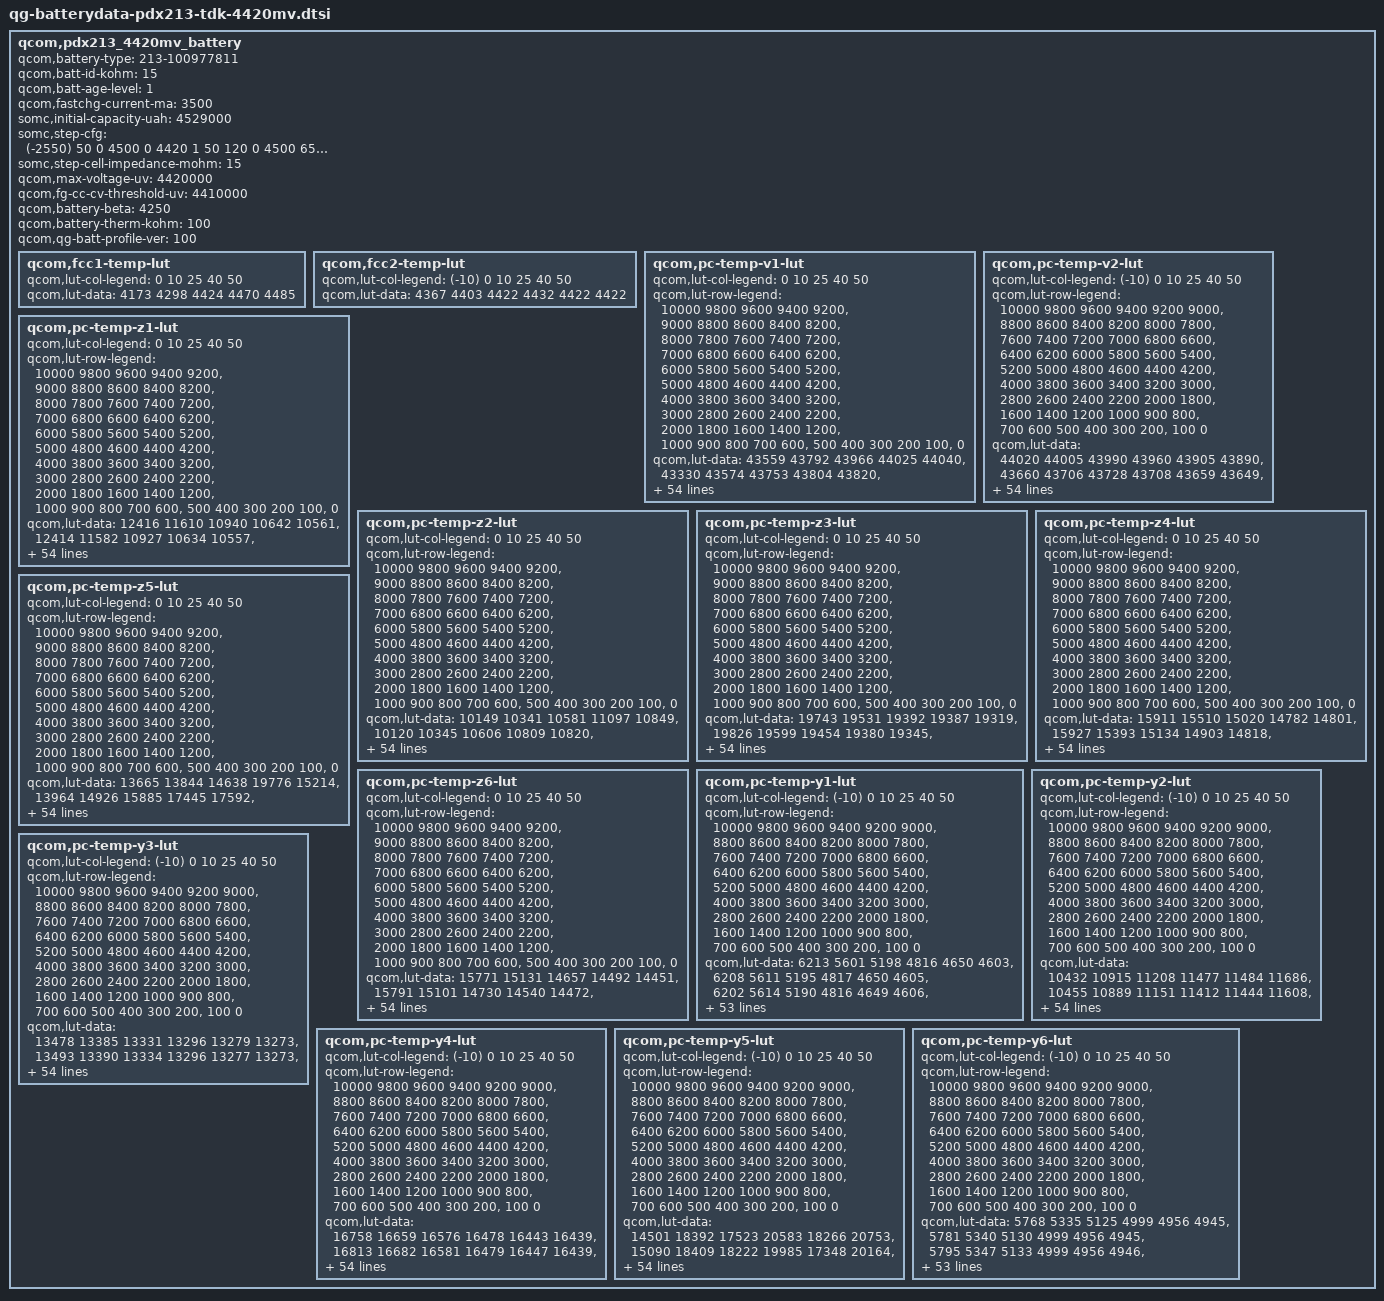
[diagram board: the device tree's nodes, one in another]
qcom,pdx213_4420mv_battery {
	/* Added or Modified by SOMC */
	qcom,battery-type = "213-100977811";
	qcom,batt-id-kohm = <15>;
	qcom,batt-age-level = <1>;
	qcom,fastchg-current-ma = <3500>;
	somc,initial-capacity-uah = <4529000>;
	somc,step-cfg = <
		(-2550) 50    0 4500    0 4420 1
		   50  120    0 4500  650 4420 2
		  120  150    0 4100 2150 4420 3
		  120  150 4100 4200 1750 4420 3
		  120  150 4200 4300 1300 4420 3
		  120  150 4300 4500  850 4420 3
		  150  200    0 4100 2400 4420 3
		  150  200 4100 4200 1950 4420 3
		  150  200 4200 4300 1750 4420 3
		  150  200 4300 4500 1300 4420 3
		  200  450    0 4200 4150 4420 3
		  200  450 4200 4250 3050 4420 3
		  200  450 4250 4350 1950 4420 3
		  200  450 4350 4500 1300 4420 3
		  450  550    0 4500 1300 4200 4
		  550 2550    0 4500    0 4200 5
	>;
	somc,step-cell-impedance-mohm = <15>;

	/* Prepared by Qualcomm */
    /* 4764138_SoMC_Licht_4375mAh_averaged_MasterSlave_Sept10th2020 */
    qcom,max-voltage-uv = <4420000>;
    qcom,fg-cc-cv-threshold-uv = <4410000>;
    /* qcom,fastchg-current-ma = <1500>; */
    /* qcom,batt-id-kohm = <0>; */
    qcom,battery-beta = <4250>;
    qcom,battery-therm-kohm = <100>;
    /* qcom,battery-type = "4764138_SoMC_Licht_4375mAh_averaged_MasterSlave_Sept10th2020"; */
    qcom,qg-batt-profile-ver = <100>;

	qcom,fcc1-temp-lut {
		qcom,lut-col-legend = <0 10 25 40 50>;
		qcom,lut-data = <4173 4298 4424 4470 4485>;
	};

	qcom,fcc2-temp-lut {
		qcom,lut-col-legend = <(-10) 0 10 25 40 50>;
		qcom,lut-data = <4367 4403 4422 4432 4422 4422>;
	};

	qcom,pc-temp-v1-lut {
		qcom,lut-col-legend = <0 10 25 40 50>;
		qcom,lut-row-legend = <10000 9800 9600 9400 9200>,
			<9000 8800 8600 8400 8200>,
			<8000 7800 7600 7400 7200>,
			<7000 6800 6600 6400 6200>,
			<6000 5800 5600 5400 5200>,
			<5000 4800 4600 4400 4200>,
			<4000 3800 3600 3400 3200>,
			<3000 2800 2600 2400 2200>,
			<2000 1800 1600 1400 1200>,
			<1000 900 800 700 600>,
			<500 400 300 200 100>,
			<0>;
		qcom,lut-data = <43559 43792 43966 44025 44040>,
			<43330 43574 43753 43804 43820>,
			<43101 43351 43542 43593 43612>,
			<42873 43123 43326 43385 43401>,
			<42643 42892 43099 43166 43183>,
			<42414 42658 42864 42935 42959>,
			<42188 42423 42628 42702 42729>,
			<41965 42190 42389 42465 42494>,
			<41747 41961 42151 42228 42256>,
			<41535 41736 41915 41992 42021>,
			<41326 41516 41683 41758 41790>,
			<41126 41300 41457 41529 41562>,
			<40936 41092 41237 41306 41337>,
			<40750 40896 41025 41090 41116>,
			<40556 40705 40818 40877 40903>,
			<40357 40515 40618 40671 40697>,
			<40179 40325 40427 40475 40499>,
			<40033 40148 40245 40290 40309>,
			<39898 39996 40072 40112 40127>,
			<39753 39848 39919 39948 39958>,
			<39599 39670 39760 39790 39799>,
			<39436 39454 39534 39599 39616>,
			<39252 39244 39235 39343 39374>,
			<39053 39042 39022 39110 39141>,
			<38889 38859 38906 38955 38974>,
			<38761 38747 38813 38831 38836>,
			<38659 38679 38716 38715 38715>,
			<38590 38617 38621 38609 38609>,
			<38539 38546 38532 38512 38512>,
			<38494 38475 38449 38422 38419>,
			<38449 38410 38375 38341 38334>,
			<38406 38349 38308 38268 38256>,
			<38365 38294 38250 38201 38185>,
			<38325 38245 38196 38140 38118>,
			<38287 38202 38151 38088 38060>,
			<38252 38162 38106 38039 38003>,
			<38218 38129 38062 37986 37937>,
			<38174 38092 38017 37931 37864>,
			<38104 38028 37957 37865 37785>,
			<38013 37930 37870 37780 37702>,
			<37907 37820 37766 37680 37610>,
			<37779 37700 37648 37564 37495>,
			<37633 37561 37511 37429 37359>,
			<37469 37392 37346 37271 37200>,
			<37320 37243 37191 37124 37059>,
			<37219 37140 37093 37028 36969>,
			<37184 37113 37066 37007 36945>,
			<37153 37088 37045 36990 36929>,
			<37123 37068 37030 36973 36916>,
			<37082 37034 37000 36940 36878>,
			<36941 36891 36830 36739 36650>,
			<36523 36471 36418 36323 36228>,
			<35956 35906 35858 35761 35666>,
			<35175 35125 35098 35001 34903>,
			<33824 33839 33933 33838 33735>,
			<30000 30000 30000 30000 30000>;
	};

	qcom,pc-temp-v2-lut {
		qcom,lut-col-legend = <(-10) 0 10 25 40 50>;
		qcom,lut-row-legend = <10000 9800 9600 9400 9200 9000>,
			<8800 8600 8400 8200 8000 7800>,
			<7600 7400 7200 7000 6800 6600>,
			<6400 6200 6000 5800 5600 5400>,
			<5200 5000 4800 4600 4400 4200>,
			<4000 3800 3600 3400 3200 3000>,
			<2800 2600 2400 2200 2000 1800>,
			<1600 1400 1200 1000 900 800>,
			<700 600 500 400 300 200>,
			<100 0>;
		qcom,lut-data = <44020 44005 43990 43960 43905 43890>,
			<43660 43706 43728 43708 43659 43649>,
			<43336 43426 43475 43462 43420 43414>,
			<43056 43166 43234 43226 43187 43184>,
			<42817 42926 43004 42998 42962 42960>,
			<42581 42689 42772 42769 42735 42734>,
			<42328 42447 42533 42533 42502 42501>,
			<42075 42205 42292 42295 42268 42266>,
			<41840 41969 42055 42060 42035 42033>,
			<41618 41735 41820 41825 41803 41801>,
			<41404 41505 41590 41594 41574 41573>,
			<41200 41274 41364 41367 41349 41351>,
			<40997 41049 41144 41145 41129 41132>,
			<40766 40855 40935 40931 40916 40920>,
			<40500 40686 40734 40723 40707 40711>,
			<40233 40494 40537 40522 40506 40511>,
			<39980 40233 40348 40324 40314 40318>,
			<39736 39954 40154 40136 40130 40133>,
			<39515 39722 39932 39965 39957 39959>,
			<39313 39518 39687 39806 39793 39795>,
			<39118 39322 39454 39616 39607 39609>,
			<38913 39126 39235 39360 39368 39374>,
			<38714 38942 39035 39109 39131 39140>,
			<38546 38776 38867 38921 38946 38955>,
			<38394 38625 38720 38762 38785 38794>,
			<38277 38485 38587 38627 38650 38658>,
			<38198 38352 38465 38512 38537 38547>,
			<38135 38230 38354 38410 38437 38447>,
			<38075 38122 38256 38314 38343 38352>,
			<38019 38024 38165 38225 38257 38262>,
			<37964 37954 38076 38143 38179 38181>,
			<37909 37906 37987 38068 38107 38108>,
			<37855 37868 37907 37998 38039 38037>,
			<37797 37831 37845 37937 37971 37971>,
			<37738 37799 37794 37880 37905 37906>,
			<37675 37762 37752 37817 37827 37821>,
			<37607 37725 37720 37748 37735 37704>,
			<37532 37680 37684 37675 37639 37586>,
			<37453 37607 37631 37597 37549 37493>,
			<37365 37501 37562 37515 37459 37406>,
			<37275 37389 37474 37423 37365 37312>,
			<37186 37272 37355 37321 37266 37213>,
			<37099 37139 37217 37198 37148 37094>,
			<37013 36986 37061 37055 37010 36956>,
			<36923 36851 36907 36922 36885 36834>,
			<36823 36756 36821 36877 36853 36803>,
			<36770 36718 36794 36859 36842 36789>,
			<36704 36680 36753 36839 36824 36774>,
			<36642 36634 36699 36811 36801 36754>,
			<36557 36550 36617 36737 36740 36678>,
			<36416 36350 36399 36492 36465 36369>,
			<36138 35911 35924 35986 35981 35881>,
			<35641 35201 35256 35335 35344 35238>,
			<34806 34127 34320 34441 34472 34354>,
			<33591 32536 32866 33159 33232 33107>,
			<31815 29576 29511 29554 29608 29574>;
	};

	qcom,pc-temp-z1-lut {
		qcom,lut-col-legend = <0 10 25 40 50>;
		qcom,lut-row-legend = <10000 9800 9600 9400 9200>,
			<9000 8800 8600 8400 8200>,
			<8000 7800 7600 7400 7200>,
			<7000 6800 6600 6400 6200>,
			<6000 5800 5600 5400 5200>,
			<5000 4800 4600 4400 4200>,
			<4000 3800 3600 3400 3200>,
			<3000 2800 2600 2400 2200>,
			<2000 1800 1600 1400 1200>,
			<1000 900 800 700 600>,
			<500 400 300 200 100>,
			<0>;
		qcom,lut-data = <12416 11610 10940 10642 10561>,
			<12414 11582 10927 10634 10557>,
			<12396 11564 10921 10629 10555>,
			<12377 11550 10914 10625 10553>,
			<12361 11539 10906 10623 10552>,
			<12345 11528 10898 10621 10551>,
			<12331 11518 10892 10619 10550>,
			<12309 11511 10887 10617 10549>,
			<12290 11504 10884 10615 10548>,
			<12274 11497 10881 10614 10547>,
			<12260 11495 10878 10613 10547>,
			<12258 11493 10877 10613 10546>,
			<12256 11492 10875 10612 10547>,
			<12252 11489 10875 10612 10549>,
			<12247 11485 10876 10612 10549>,
			<12241 11482 10878 10613 10549>,
			<12237 11477 10878 10613 10549>,
			<12241 11474 10878 10614 10550>,
			<12250 11481 10878 10615 10551>,
			<12254 11493 10880 10617 10553>,
			<12253 11498 10884 10618 10554>,
			<12253 11500 10887 10620 10556>,
			<12263 11503 10891 10623 10558>,
			<12285 11506 10895 10626 10561>,
			<12297 11510 10899 10629 10564>,
			<12298 11515 10904 10632 10566>,
			<12298 11523 10908 10635 10568>,
			<12298 11528 10913 10638 10570>,
			<12301 11528 10917 10640 10572>,
			<12303 11528 10921 10643 10574>,
			<12306 11529 10926 10646 10576>,
			<12308 11535 10929 10648 10577>,
			<12311 11543 10933 10650 10579>,
			<12322 11549 10937 10652 10580>,
			<12335 11555 10941 10655 10582>,
			<12343 11561 10946 10657 10584>,
			<12349 11566 10951 10660 10587>,
			<12356 11572 10957 10663 10589>,
			<12369 11580 10963 10666 10591>,
			<12386 11593 10968 10669 10593>,
			<12408 11605 10973 10672 10594>,
			<12440 11616 10980 10674 10596>,
			<12445 11623 10987 10676 10598>,
			<12418 11623 10991 10678 10599>,
			<12426 11629 10998 10681 10601>,
			<12433 11639 11003 10683 10601>,
			<12439 11638 11002 10683 10603>,
			<12412 11629 11003 10683 10602>,
			<12427 11644 11003 10684 10603>,
			<12438 11640 11007 10687 10606>,
			<12456 11660 11024 10692 10609>,
			<12461 11670 11034 10699 10615>,
			<12487 11703 11048 10710 10624>,
			<12542 11736 11075 10726 10637>,
			<12542 11736 11075 10726 10637>,
			<12542 11736 11075 10726 10637>;
	};

	qcom,pc-temp-z2-lut {
		qcom,lut-col-legend = <0 10 25 40 50>;
		qcom,lut-row-legend = <10000 9800 9600 9400 9200>,
			<9000 8800 8600 8400 8200>,
			<8000 7800 7600 7400 7200>,
			<7000 6800 6600 6400 6200>,
			<6000 5800 5600 5400 5200>,
			<5000 4800 4600 4400 4200>,
			<4000 3800 3600 3400 3200>,
			<3000 2800 2600 2400 2200>,
			<2000 1800 1600 1400 1200>,
			<1000 900 800 700 600>,
			<500 400 300 200 100>,
			<0>;
		qcom,lut-data = <10149 10341 10581 11097 10849>,
			<10120 10345 10606 10809 10820>,
			<10093 10331 10562 10811 10829>,
			<10074 10289 10516 10734 10851>,
			<10063 10247 10492 10708 10857>,
			<10056 10224 10476 10708 10832>,
			<10052 10207 10477 10711 10809>,
			<10049 10204 10495 10717 10813>,
			<10048 10228 10513 10725 10823>,
			<10053 10261 10522 10731 10815>,
			<10065 10279 10530 10735 10747>,
			<10077 10292 10539 10728 10701>,
			<10088 10306 10554 10660 10703>,
			<10098 10323 10568 10587 10708>,
			<10108 10340 10579 10585 10715>,
			<10117 10354 10588 10601 10738>,
			<10135 10366 10595 10619 10754>,
			<10216 10375 10600 10644 10761>,
			<10305 10382 10604 10666 10769>,
			<10307 10389 10607 10672 10779>,
			<10246 10404 10610 10673 10802>,
			<10207 10438 10620 10691 10839>,
			<10224 10459 10645 10757 10948>,
			<10255 10440 10656 10808 11036>,
			<10277 10408 10646 10852 11013>,
			<10290 10402 10636 10925 10949>,
			<10299 10413 10640 10921 10893>,
			<10301 10423 10653 10808 10805>,
			<10300 10424 10656 10722 10730>,
			<10300 10424 10614 10700 10698>,
			<10304 10425 10570 10686 10675>,
			<10311 10433 10571 10692 10673>,
			<10317 10444 10584 10733 10691>,
			<10325 10456 10605 10767 10716>,
			<10332 10471 10673 10787 10770>,
			<10338 10482 10735 10809 10850>,
			<10343 10490 10744 10847 10925>,
			<10349 10499 10741 10923 11001>,
			<10359 10516 10751 10981 11058>,
			<10369 10539 10786 11016 11121>,
			<10369 10548 10813 11043 11169>,
			<10359 10542 10810 11062 11138>,
			<10357 10538 10803 11076 11065>,
			<10371 10546 10819 11071 11084>,
			<10579 10632 10849 11038 11099>,
			<10417 10685 10887 10956 11090>,
			<10267 10712 10841 10972 11082>,
			<10197 10752 10813 10967 11050>,
			<10121 10982 10808 10952 11130>,
			<10003 11047 10811 11016 11246>,
			<10001 10950 11007 10886 10867>,
			<9865 10915 10960 10756 10729>,
			<9700 10814 10888 10674 10608>,
			<9584 10597 10811 10611 10570>,
			<9584 10597 10811 10611 10570>,
			<9584 10597 10811 10611 10570>;
	};

	qcom,pc-temp-z3-lut {
		qcom,lut-col-legend = <0 10 25 40 50>;
		qcom,lut-row-legend = <10000 9800 9600 9400 9200>,
			<9000 8800 8600 8400 8200>,
			<8000 7800 7600 7400 7200>,
			<7000 6800 6600 6400 6200>,
			<6000 5800 5600 5400 5200>,
			<5000 4800 4600 4400 4200>,
			<4000 3800 3600 3400 3200>,
			<3000 2800 2600 2400 2200>,
			<2000 1800 1600 1400 1200>,
			<1000 900 800 700 600>,
			<500 400 300 200 100>,
			<0>;
		qcom,lut-data = <19743 19531 19392 19387 19319>,
			<19826 19599 19454 19380 19345>,
			<19866 19631 19478 19401 19367>,
			<19879 19647 19487 19409 19382>,
			<19881 19655 19487 19410 19385>,
			<19881 19655 19487 19406 19377>,
			<19880 19652 19484 19402 19368>,
			<19876 19647 19473 19396 19366>,
			<19870 19631 19463 19389 19364>,
			<19859 19612 19458 19386 19361>,
			<19841 19603 19454 19383 19352>,
			<19825 19598 19448 19380 19346>,
			<19807 19592 19438 19368 19343>,
			<19793 19584 19432 19357 19342>,
			<19787 19577 19431 19356 19338>,
			<19784 19572 19430 19355 19332>,
			<19782 19570 19428 19354 19328>,
			<19779 19567 19425 19347 19327>,
			<19772 19564 19422 19341 19326>,
			<19769 19560 19419 19340 19325>,
			<19767 19563 19416 19340 19323>,
			<19768 19581 19421 19340 19322>,
			<19774 19593 19440 19345 19326>,
			<19781 19591 19448 19352 19332>,
			<19784 19585 19429 19361 19349>,
			<19782 19580 19409 19373 19377>,
			<19777 19571 19415 19383 19384>,
			<19772 19566 19438 19392 19377>,
			<19763 19570 19451 19397 19368>,
			<19756 19578 19455 19393 19362>,
			<19751 19581 19457 19387 19356>,
			<19747 19580 19454 19380 19351>,
			<19743 19579 19446 19374 19345>,
			<19739 19576 19438 19368 19339>,
			<19735 19569 19431 19361 19333>,
			<19731 19563 19425 19355 19328>,
			<19726 19558 19423 19351 19328>,
			<19721 19554 19422 19349 19329>,
			<19713 19549 19420 19348 19330>,
			<19703 19544 19416 19348 19331>,
			<19694 19540 19411 19348 19331>,
			<19685 19534 19407 19348 19330>,
			<19672 19528 19404 19347 19327>,
			<19648 19520 19402 19348 19333>,
			<19548 19486 19396 19345 19333>,
			<19414 19470 19383 19336 19318>,
			<19347 19451 19379 19328 19317>,
			<19328 19429 19381 19328 19316>,
			<19315 19336 19373 19326 19306>,
			<19293 19330 19370 19323 19302>,
			<19292 19370 19348 19341 19336>,
			<19297 19334 19363 19348 19341>,
			<19302 19322 19356 19358 19343>,
			<19315 19339 19364 19357 19345>,
			<19315 19339 19364 19357 19345>,
			<19315 19339 19364 19357 19345>;
	};

	qcom,pc-temp-z4-lut {
		qcom,lut-col-legend = <0 10 25 40 50>;
		qcom,lut-row-legend = <10000 9800 9600 9400 9200>,
			<9000 8800 8600 8400 8200>,
			<8000 7800 7600 7400 7200>,
			<7000 6800 6600 6400 6200>,
			<6000 5800 5600 5400 5200>,
			<5000 4800 4600 4400 4200>,
			<4000 3800 3600 3400 3200>,
			<3000 2800 2600 2400 2200>,
			<2000 1800 1600 1400 1200>,
			<1000 900 800 700 600>,
			<500 400 300 200 100>,
			<0>;
		qcom,lut-data = <15911 15510 15020 14782 14801>,
			<15927 15393 15134 14903 14818>,
			<15728 15283 15054 14892 14832>,
			<15545 15175 14964 14841 14792>,
			<15419 15081 14900 14806 14766>,
			<15315 15009 14846 14781 14753>,
			<15228 14950 14820 14764 14744>,
			<15152 14910 14808 14756 14736>,
			<15089 14885 14797 14750 14729>,
			<15033 14867 14784 14742 14724>,
			<14985 14853 14772 14731 14721>,
			<14957 14843 14763 14723 14717>,
			<14941 14834 14757 14721 14709>,
			<14932 14824 14750 14718 14700>,
			<14935 14817 14742 14711 14693>,
			<14945 14816 14733 14699 14687>,
			<14950 14818 14726 14691 14681>,
			<14920 14818 14720 14687 14672>,
			<14878 14802 14717 14684 14665>,
			<14865 14781 14715 14681 14661>,
			<14864 14784 14714 14678 14659>,
			<14868 14825 14749 14686 14662>,
			<14900 14875 14869 14773 14731>,
			<14972 14935 14925 14844 14799>,
			<15021 14994 14922 14834 14785>,
			<15045 15003 14916 14805 14744>,
			<15060 14971 14895 14779 14723>,
			<15057 14934 14846 14751 14715>,
			<15038 14904 14810 14730 14708>,
			<15015 14876 14786 14719 14700>,
			<14995 14860 14770 14710 14693>,
			<14976 14851 14763 14703 14686>,
			<14959 14845 14759 14697 14679>,
			<14946 14842 14756 14695 14675>,
			<14934 14841 14755 14695 14675>,
			<14921 14838 14754 14696 14674>,
			<14907 14830 14755 14701 14680>,
			<14894 14822 14758 14711 14699>,
			<14884 14819 14762 14719 14708>,
			<14874 14819 14769 14724 14704>,
			<14861 14816 14774 14727 14700>,
			<14841 14796 14765 14723 14697>,
			<14820 14772 14748 14715 14695>,
			<14798 14757 14741 14713 14694>,
			<14795 14728 14725 14708 14691>,
			<14905 14706 14702 14697 14685>,
			<14974 14708 14689 14690 14676>,
			<14986 14718 14670 14668 14657>,
			<14993 14814 14659 14648 14644>,
			<15006 14816 14657 14647 14643>,
			<15004 14774 14703 14658 14641>,
			<15018 14827 14694 14657 14642>,
			<15023 14846 14703 14649 14643>,
			<15033 14841 14694 14651 14641>,
			<15033 14841 14694 14651 14641>,
			<15033 14841 14694 14651 14641>;
	};

	qcom,pc-temp-z5-lut {
		qcom,lut-col-legend = <0 10 25 40 50>;
		qcom,lut-row-legend = <10000 9800 9600 9400 9200>,
			<9000 8800 8600 8400 8200>,
			<8000 7800 7600 7400 7200>,
			<7000 6800 6600 6400 6200>,
			<6000 5800 5600 5400 5200>,
			<5000 4800 4600 4400 4200>,
			<4000 3800 3600 3400 3200>,
			<3000 2800 2600 2400 2200>,
			<2000 1800 1600 1400 1200>,
			<1000 900 800 700 600>,
			<500 400 300 200 100>,
			<0>;
		qcom,lut-data = <13665 13844 14638 19776 15214>,
			<13964 14926 15885 17445 17592>,
			<14458 15707 16454 18360 18625>,
			<14971 16263 17042 18755 20537>,
			<15368 16794 17875 19293 21192>,
			<15767 17471 18708 20009 20907>,
			<16277 18225 18920 20359 20633>,
			<16919 18772 18881 20187 20812>,
			<17598 19117 18871 19935 21206>,
			<18359 19408 19221 20043 21164>,
			<19222 19748 19710 20609 20240>,
			<19724 20182 19742 20867 19615>,
			<19876 20502 19477 19892 19955>,
			<20014 20800 19320 18737 20496>,
			<20402 21031 19822 19013 20498>,
			<21234 21038 20727 20199 20097>,
			<21721 21017 21444 20647 19899>,
			<21662 21040 22115 20051 20740>,
			<21535 22091 22738 19487 22019>,
			<22033 24296 23206 19927 22845>,
			<25901 27365 23775 21010 23526>,
			<30543 32826 25781 21309 23575>,
			<33915 36134 30097 20531 20756>,
			<36877 34095 31683 19627 17980>,
			<37840 29807 25278 18544 18477>,
			<36505 26753 18202 17179 20055>,
			<34310 24083 17907 17197 20643>,
			<32390 22605 19017 19068 20701>,
			<30363 23342 20479 21062 20778>,
			<29269 25276 22892 22286 21191>,
			<29170 27163 25440 23402 22035>,
			<29129 29250 27105 24829 23000>,
			<29165 30914 28433 26646 24259>,
			<29488 31670 29469 27792 25359>,
			<29928 32185 30369 28390 26400>,
			<30316 32303 30987 28786 27215>,
			<30738 32014 31223 28382 27057>,
			<31039 31676 31228 26858 26040>,
			<31272 31550 30722 25489 25270>,
			<31447 31444 28200 24163 24610>,
			<31243 31282 26082 23221 24107>,
			<29982 30746 25805 23088 23589>,
			<28553 30189 25634 23059 22631>,
			<26861 29799 24914 22155 23110>,
			<20501 27551 24975 21227 22360>,
			<14498 26586 24245 20208 18474>,
			<12239 21547 24606 19238 18968>,
			<11919 18803 27431 21406 21518>,
			<11766 12919 25400 25032 21663>,
			<11571 12795 24684 24261 20982>,
			<11575 14777 16981 22187 28375>,
			<11565 12827 17482 22602 28618>,
			<11520 12391 16408 25446 27832>,
			<11997 12861 16969 23529 27312>,
			<11997 12861 16969 23529 27312>,
			<11997 12861 16969 23529 27312>;
	};

	qcom,pc-temp-z6-lut {
		qcom,lut-col-legend = <0 10 25 40 50>;
		qcom,lut-row-legend = <10000 9800 9600 9400 9200>,
			<9000 8800 8600 8400 8200>,
			<8000 7800 7600 7400 7200>,
			<7000 6800 6600 6400 6200>,
			<6000 5800 5600 5400 5200>,
			<5000 4800 4600 4400 4200>,
			<4000 3800 3600 3400 3200>,
			<3000 2800 2600 2400 2200>,
			<2000 1800 1600 1400 1200>,
			<1000 900 800 700 600>,
			<500 400 300 200 100>,
			<0>;
		qcom,lut-data = <15771 15131 14657 14492 14451>,
			<15791 15101 14730 14540 14472>,
			<15704 15066 14705 14543 14486>,
			<15617 15020 14675 14527 14479>,
			<15549 14974 14649 14514 14471>,
			<15488 14938 14623 14501 14461>,
			<15435 14906 14606 14491 14452>,
			<15387 14879 14595 14483 14447>,
			<15345 14855 14585 14477 14443>,
			<15303 14837 14576 14471 14439>,
			<15266 14825 14568 14466 14433>,
			<15240 14816 14560 14459 14427>,
			<15222 14808 14552 14452 14422>,
			<15212 14798 14545 14445 14418>,
			<15211 14790 14540 14440 14412>,
			<15213 14787 14536 14435 14407>,
			<15214 14785 14532 14430 14402>,
			<15200 14783 14528 14425 14397>,
			<15180 14775 14525 14421 14394>,
			<15175 14767 14523 14419 14392>,
			<15177 14770 14522 14418 14390>,
			<15180 14798 14540 14422 14391>,
			<15197 14829 14603 14464 14425>,
			<15236 14856 14631 14498 14458>,
			<15261 14880 14624 14498 14459>,
			<15273 14883 14612 14494 14457>,
			<15280 14866 14603 14490 14455>,
			<15278 14849 14596 14483 14448>,
			<15267 14840 14590 14476 14440>,
			<15255 14833 14583 14469 14434>,
			<15245 14829 14578 14463 14427>,
			<15237 14827 14572 14456 14421>,
			<15231 14826 14566 14451 14415>,
			<15227 14824 14562 14446 14410>,
			<15224 14821 14558 14442 14406>,
			<15221 14819 14556 14439 14403>,
			<15217 14816 14557 14440 14405>,
			<15216 14813 14558 14443 14414>,
			<15216 14814 14559 14446 14419>,
			<15215 14816 14561 14449 14418>,
			<15215 14816 14562 14450 14417>,
			<15212 14809 14558 14449 14415>,
			<15208 14801 14550 14445 14413>,
			<15198 14796 14547 14445 14415>,
			<15160 14776 14539 14442 14415>,
			<15151 14760 14524 14433 14405>,
			<15146 14754 14517 14426 14400>,
			<15146 14748 14510 14417 14392>,
			<15150 14744 14502 14407 14380>,
			<15151 14747 14500 14405 14378>,
			<15163 14757 14512 14420 14396>,
			<15187 14770 14519 14425 14401>,
			<15211 14783 14524 14429 14404>,
			<15258 14810 14530 14432 14407>,
			<15258 14810 14530 14432 14407>,
			<15258 14810 14530 14432 14407>;
	};

	qcom,pc-temp-y1-lut {
		qcom,lut-col-legend = <(-10) 0 10 25 40 50>;
		qcom,lut-row-legend = <10000 9800 9600 9400 9200 9000>,
			<8800 8600 8400 8200 8000 7800>,
			<7600 7400 7200 7000 6800 6600>,
			<6400 6200 6000 5800 5600 5400>,
			<5200 5000 4800 4600 4400 4200>,
			<4000 3800 3600 3400 3200 3000>,
			<2800 2600 2400 2200 2000 1800>,
			<1600 1400 1200 1000 900 800>,
			<700 600 500 400 300 200>,
			<100 0>;
		qcom,lut-data = <6213 5601 5198 4816 4650 4603>,
			<6208 5611 5195 4817 4650 4605>,
			<6202 5614 5190 4816 4649 4606>,
			<6196 5612 5186 4815 4649 4607>,
			<6192 5609 5183 4813 4648 4607>,
			<6191 5607 5181 4810 4647 4607>,
			<6196 5602 5179 4807 4646 4606>,
			<6205 5595 5179 4804 4645 4605>,
			<6207 5593 5176 4802 4644 4605>,
			<6206 5592 5170 4800 4643 4605>,
			<6204 5591 5167 4799 4643 4605>,
			<6207 5593 5167 4798 4643 4605>,
			<6212 5595 5169 4796 4643 4605>,
			<6212 5596 5167 4795 4642 4605>,
			<6211 5597 5162 4794 4642 4606>,
			<6211 5598 5159 4793 4642 4606>,
			<6217 5605 5161 4794 4642 4606>,
			<6226 5614 5163 4795 4643 4606>,
			<6224 5613 5163 4796 4643 4607>,
			<6209 5607 5163 4797 4644 4607>,
			<6199 5604 5164 4798 4645 4608>,
			<6199 5611 5164 4800 4646 4608>,
			<6199 5620 5165 4803 4647 4609>,
			<6200 5623 5168 4805 4648 4609>,
			<6204 5625 5173 4807 4649 4610>,
			<6208 5626 5176 4810 4650 4611>,
			<6204 5627 5178 4812 4651 4612>,
			<6197 5629 5180 4815 4652 4613>,
			<6197 5628 5183 4819 4654 4614>,
			<6204 5623 5189 4823 4656 4615>,
			<6208 5621 5193 4826 4658 4616>,
			<6202 5627 5196 4828 4659 4618>,
			<6193 5634 5198 4830 4661 4619>,
			<6190 5634 5197 4833 4663 4620>,
			<6189 5631 5194 4837 4665 4622>,
			<6188 5630 5193 4840 4666 4623>,
			<6195 5630 5196 4843 4667 4624>,
			<6208 5631 5200 4845 4669 4625>,
			<6211 5632 5204 4847 4670 4625>,
			<6211 5636 5207 4849 4671 4626>,
			<6210 5637 5212 4852 4672 4627>,
			<6220 5635 5219 4856 4673 4628>,
			<6230 5633 5227 4859 4675 4629>,
			<6210 5634 5239 4862 4676 4630>,
			<6213 5640 5233 4867 4677 4630>,
			<6237 5654 5238 4870 4679 4632>,
			<6258 5674 5239 4871 4680 4632>,
			<6298 5654 5244 4875 4681 4633>,
			<6339 5670 5252 4880 4681 4633>,
			<6409 5675 5242 4884 4682 4633>,
			<6407 5690 5245 4886 4682 4634>,
			<6464 5735 5268 4892 4685 4638>,
			<6516 5803 5282 4909 4691 4642>,
			<6583 5833 5334 4932 4698 4647>,
			<6583 5833 5334 4932 4698 4647>,
			<6583 5833 5334 4932 4698 4647>;
	};

	qcom,pc-temp-y2-lut {
		qcom,lut-col-legend = <(-10) 0 10 25 40 50>;
		qcom,lut-row-legend = <10000 9800 9600 9400 9200 9000>,
			<8800 8600 8400 8200 8000 7800>,
			<7600 7400 7200 7000 6800 6600>,
			<6400 6200 6000 5800 5600 5400>,
			<5200 5000 4800 4600 4400 4200>,
			<4000 3800 3600 3400 3200 3000>,
			<2800 2600 2400 2200 2000 1800>,
			<1600 1400 1200 1000 900 800>,
			<700 600 500 400 300 200>,
			<100 0>;
		qcom,lut-data = <10432 10915 11208 11477 11484 11686>,
			<10455 10889 11151 11412 11444 11608>,
			<10492 10863 11097 11345 11381 11522>,
			<10532 10838 11046 11282 11312 11439>,
			<10564 10817 11002 11229 11255 11367>,
			<10579 10801 10965 11190 11228 11315>,
			<10579 10786 10933 11163 11222 11273>,
			<10577 10775 10908 11143 11218 11242>,
			<10596 10775 10895 11127 11221 11239>,
			<10697 10785 10886 11114 11234 11239>,
			<10770 10797 10883 11109 11246 11240>,
			<10768 10811 10895 11118 11252 11249>,
			<10758 10829 10919 11135 11257 11264>,
			<10763 10867 10945 11149 11264 11275>,
			<10792 10941 10979 11165 11279 11284>,
			<10816 10983 11020 11188 11295 11299>,
			<10829 10993 11080 11234 11328 11339>,
			<10842 10999 11131 11291 11377 11399>,
			<10848 11011 11142 11347 11452 11473>,
			<10851 11033 11144 11405 11567 11567>,
			<10848 11049 11148 11421 11619 11606>,
			<10685 11059 11173 11402 11621 11579>,
			<10383 11067 11203 11384 11613 11552>,
			<10206 11076 11221 11388 11585 11579>,
			<9902 11088 11239 11402 11533 11639>,
			<9711 11092 11257 11420 11517 11678>,
			<9697 11077 11276 11449 11553 11696>,
			<9690 11060 11291 11483 11610 11715>,
			<9684 11075 11298 11514 11674 11759>,
			<9680 11128 11303 11543 11753 11829>,
			<9677 11150 11304 11563 11818 11905>,
			<9674 11109 11300 11581 11876 12002>,
			<9672 11046 11295 11593 11912 12073>,
			<9670 10997 11289 11608 11921 12107>,
			<9668 10950 11281 11625 11924 12142>,
			<9666 10901 11267 11624 11911 12139>,
			<9666 10856 11240 11602 11839 12031>,
			<9665 10792 11207 11575 11761 11934>,
			<9664 10509 11173 11551 11710 11911>,
			<9663 9944 11133 11527 11669 11896>,
			<9662 9715 11080 11507 11658 11899>,
			<9661 9693 11004 11489 11683 11914>,
			<9661 9681 10918 11460 11687 11903>,
			<9660 9673 10820 11416 11687 11858>,
			<9659 9669 10699 11374 11640 11745>,
			<9658 9666 10617 11353 11518 11564>,
			<9656 9664 10546 11341 11511 11512>,
			<9654 9661 10235 11327 11464 11383>,
			<9653 9659 9913 11276 11437 11428>,
			<9651 9657 9768 11262 11476 11475>,
			<9650 9653 9699 11246 11439 11356>,
			<9649 9650 9673 11156 11310 11276>,
			<9648 9649 9659 11026 11247 11193>,
			<9648 9649 9654 10935 11154 11056>,
			<9648 9649 9654 10935 11154 11056>,
			<9648 9649 9654 10935 11154 11056>;
	};

	qcom,pc-temp-y3-lut {
		qcom,lut-col-legend = <(-10) 0 10 25 40 50>;
		qcom,lut-row-legend = <10000 9800 9600 9400 9200 9000>,
			<8800 8600 8400 8200 8000 7800>,
			<7600 7400 7200 7000 6800 6600>,
			<6400 6200 6000 5800 5600 5400>,
			<5200 5000 4800 4600 4400 4200>,
			<4000 3800 3600 3400 3200 3000>,
			<2800 2600 2400 2200 2000 1800>,
			<1600 1400 1200 1000 900 800>,
			<700 600 500 400 300 200>,
			<100 0>;
		qcom,lut-data = <13478 13385 13331 13296 13279 13273>,
			<13493 13390 13334 13296 13277 13273>,
			<13507 13396 13338 13297 13276 13273>,
			<13519 13401 13341 13297 13276 13273>,
			<13527 13406 13344 13298 13277 13274>,
			<13530 13409 13346 13299 13279 13275>,
			<13527 13411 13348 13300 13281 13275>,
			<13522 13412 13349 13301 13285 13276>,
			<13524 13412 13350 13302 13286 13277>,
			<13539 13409 13351 13303 13287 13278>,
			<13550 13408 13351 13303 13288 13278>,
			<13522 13408 13351 13303 13288 13281>,
			<13479 13409 13349 13303 13289 13284>,
			<13471 13407 13349 13304 13289 13284>,
			<13480 13400 13349 13307 13288 13285>,
			<13487 13394 13350 13308 13288 13285>,
			<13477 13392 13351 13305 13290 13286>,
			<13460 13390 13352 13302 13292 13286>,
			<13449 13387 13350 13303 13292 13286>,
			<13442 13382 13344 13307 13292 13287>,
			<13436 13377 13338 13308 13291 13286>,
			<13428 13373 13333 13304 13288 13282>,
			<13420 13369 13329 13300 13284 13277>,
			<13413 13365 13327 13296 13281 13275>,
			<13405 13362 13325 13294 13279 13273>,
			<13400 13359 13324 13293 13278 13273>,
			<13403 13357 13322 13293 13278 13274>,
			<13413 13354 13321 13293 13277 13275>,
			<13426 13347 13321 13293 13277 13274>,
			<13447 13332 13320 13293 13278 13273>,
			<13473 13325 13320 13293 13278 13273>,
			<13500 13329 13318 13293 13278 13273>,
			<13533 13335 13317 13292 13278 13273>,
			<13571 13342 13317 13293 13279 13274>,
			<13614 13351 13317 13293 13279 13275>,
			<13663 13360 13317 13293 13279 13275>,
			<13717 13366 13321 13293 13278 13273>,
			<13776 13372 13326 13292 13277 13272>,
			<13839 13382 13329 13292 13276 13272>,
			<13908 13396 13331 13291 13276 13273>,
			<13979 13414 13333 13291 13276 13274>,
			<14051 13440 13334 13291 13277 13275>,
			<14130 13474 13335 13291 13277 13275>,
			<14219 13521 13337 13292 13277 13275>,
			<14338 13584 13340 13293 13274 13271>,
			<14405 13637 13340 13293 13280 13275>,
			<14595 13720 13347 13295 13282 13276>,
			<14897 13841 13351 13298 13283 13281>,
			<15420 14006 13361 13306 13290 13284>,
			<16322 14274 13397 13310 13291 13284>,
			<18171 14910 13457 13310 13285 13280>,
			<22536 16580 13570 13308 13285 13281>,
			<35794 22087 13975 13316 13287 13282>,
			<65535 46071 15677 13330 13292 13287>,
			<65535 46071 15677 13330 13292 13287>,
			<65535 46071 15677 13330 13292 13287>;
	};

	qcom,pc-temp-y4-lut {
		qcom,lut-col-legend = <(-10) 0 10 25 40 50>;
		qcom,lut-row-legend = <10000 9800 9600 9400 9200 9000>,
			<8800 8600 8400 8200 8000 7800>,
			<7600 7400 7200 7000 6800 6600>,
			<6400 6200 6000 5800 5600 5400>,
			<5200 5000 4800 4600 4400 4200>,
			<4000 3800 3600 3400 3200 3000>,
			<2800 2600 2400 2200 2000 1800>,
			<1600 1400 1200 1000 900 800>,
			<700 600 500 400 300 200>,
			<100 0>;
		qcom,lut-data = <16758 16659 16576 16478 16443 16439>,
			<16813 16682 16581 16479 16447 16439>,
			<16885 16712 16589 16480 16450 16439>,
			<16960 16743 16597 16482 16451 16440>,
			<17022 16768 16604 16483 16452 16440>,
			<17057 16782 16606 16484 16452 16441>,
			<17071 16786 16605 16485 16450 16442>,
			<17080 16789 16604 16487 16448 16443>,
			<17077 16795 16605 16489 16448 16445>,
			<17057 16807 16610 16494 16451 16448>,
			<17044 16818 16617 16500 16455 16451>,
			<17111 16824 16630 16508 16460 16452>,
			<17218 16832 16649 16517 16466 16452>,
			<17223 16859 16671 16525 16473 16455>,
			<17115 16928 16700 16534 16482 16461>,
			<17009 16962 16720 16545 16491 16468>,
			<16951 16895 16733 16567 16498 16475>,
			<16904 16799 16740 16593 16506 16482>,
			<16867 16760 16728 16617 16524 16496>,
			<16837 16740 16682 16641 16552 16515>,
			<16808 16719 16638 16645 16561 16522>,
			<16768 16691 16599 16586 16532 16505>,
			<16730 16664 16567 16520 16495 16482>,
			<16725 16642 16552 16496 16474 16465>,
			<16738 16624 16543 16480 16456 16449>,
			<16748 16605 16537 16477 16451 16445>,
			<16755 16576 16534 16479 16455 16447>,
			<16762 16553 16532 16483 16461 16450>,
			<16764 16554 16531 16488 16468 16456>,
			<16763 16563 16531 16494 16477 16466>,
			<16762 16568 16529 16502 16487 16475>,
			<16762 16573 16518 16510 16499 16484>,
			<16763 16580 16508 16518 16508 16492>,
			<16764 16586 16509 16527 16510 16499>,
			<16765 16597 16512 16535 16512 16503>,
			<16766 16611 16519 16534 16511 16502>,
			<16767 16632 16537 16521 16496 16482>,
			<16768 16655 16558 16508 16480 16464>,
			<16769 16680 16577 16496 16471 16459>,
			<16770 16708 16594 16487 16464 16457>,
			<16772 16716 16600 16486 16463 16456>,
			<16778 16709 16601 16490 16464 16457>,
			<16787 16695 16601 16493 16464 16456>,
			<16796 16670 16598 16495 16462 16454>,
			<16810 16665 16579 16474 16444 16435>,
			<16790 16660 16565 16477 16447 16442>,
			<16825 16671 16582 16490 16455 16449>,
			<16904 16693 16617 16507 16465 16455>,
			<17029 16724 16664 16525 16482 16496>,
			<17247 16770 16714 16547 16529 16537>,
			<17686 16916 16742 16540 16479 16462>,
			<18772 17380 16739 16511 16453 16447>,
			<23762 20366 16828 16541 16459 16454>,
			<65535 54632 18262 16601 16491 16484>,
			<65535 54632 18262 16601 16491 16484>,
			<65535 54632 18262 16601 16491 16484>;
	};

	qcom,pc-temp-y5-lut {
		qcom,lut-col-legend = <(-10) 0 10 25 40 50>;
		qcom,lut-row-legend = <10000 9800 9600 9400 9200 9000>,
			<8800 8600 8400 8200 8000 7800>,
			<7600 7400 7200 7000 6800 6600>,
			<6400 6200 6000 5800 5600 5400>,
			<5200 5000 4800 4600 4400 4200>,
			<4000 3800 3600 3400 3200 3000>,
			<2800 2600 2400 2200 2000 1800>,
			<1600 1400 1200 1000 900 800>,
			<700 600 500 400 300 200>,
			<100 0>;
		qcom,lut-data = <14501 18392 17523 20583 18266 20753>,
			<15090 18409 18222 19985 17348 20164>,
			<16002 18388 18581 19254 16794 19572>,
			<16976 18337 18688 18508 16512 19020>,
			<17754 18261 18635 17868 16411 18550>,
			<18075 18169 18510 17451 16405 18204>,
			<18000 18041 18199 17219 17697 17994>,
			<17882 17859 17736 16998 19471 17810>,
			<18192 17594 17312 16643 19608 17454>,
			<19992 17177 16840 16107 19026 16868>,
			<21181 16861 16387 15581 18350 16614>,
			<20081 16645 15880 14995 17667 17517>,
			<18344 16496 15497 14556 16928 18640>,
			<18647 16728 15490 14535 16122 18487>,
			<22260 17769 15645 14589 15229 17457>,
			<24699 18859 15977 14599 14891 16722>,
			<23569 19799 18543 14234 14945 16302>,
			<21721 20690 21564 13845 15020 16009>,
			<21443 21395 22444 14493 15054 15857>,
			<22100 21997 22906 16689 15095 15548>,
			<22701 22456 23018 18879 15328 15529>,
			<21960 22811 22707 21469 18607 17577>,
			<20127 23085 22337 23256 21950 19707>,
			<18462 23269 22210 22758 21998 19712>,
			<14736 23424 22191 21332 21404 19324>,
			<12406 23625 22191 20712 20636 19151>,
			<12305 24044 21983 20563 19292 19197>,
			<12252 24403 21822 20492 18178 19231>,
			<12269 22576 22278 20545 17898 18508>,
			<12436 16810 23192 20696 17744 16916>,
			<12643 14181 23465 20750 17728 16426>,
			<12856 14569 23281 20795 17920 16567>,
			<13105 15326 22957 20893 18231 16800>,
			<13329 16347 22143 21453 18701 17482>,
			<13595 18067 20937 22447 19333 18571>,
			<13766 19425 20718 23128 19776 18831>,
			<13852 20662 21533 23700 20143 18586>,
			<13928 21479 22173 23976 20340 18418>,
			<13894 20230 21958 23051 20016 18811>,
			<13626 16775 21379 21364 19336 19696>,
			<13331 15309 20734 20309 19131 20502>,
			<13100 15193 19818 19526 19198 21288>,
			<12945 15016 19269 18996 19445 22358>,
			<13074 14619 19083 18767 20100 23385>,
			<13137 13943 19260 20862 19191 20511>,
			<13151 13610 18366 20278 19967 17943>,
			<13028 13747 18272 18052 18494 16902>,
			<12401 13861 15956 17158 17441 20722>,
			<12052 14092 14457 18024 21478 21676>,
			<11467 13974 14238 19001 20474 18693>,
			<10681 12944 14316 20274 18822 19687>,
			<9769 11125 14202 20864 22520 23753>,
			<9116 9530 13680 21399 23330 23903>,
			<8827 8908 10498 23559 26820 27204>,
			<8827 8908 10498 23559 26820 27204>,
			<8827 8908 10498 23559 26820 27204>;
	};

	qcom,pc-temp-y6-lut {
		qcom,lut-col-legend = <(-10) 0 10 25 40 50>;
		qcom,lut-row-legend = <10000 9800 9600 9400 9200 9000>,
			<8800 8600 8400 8200 8000 7800>,
			<7600 7400 7200 7000 6800 6600>,
			<6400 6200 6000 5800 5600 5400>,
			<5200 5000 4800 4600 4400 4200>,
			<4000 3800 3600 3400 3200 3000>,
			<2800 2600 2400 2200 2000 1800>,
			<1600 1400 1200 1000 900 800>,
			<700 600 500 400 300 200>,
			<100 0>;
		qcom,lut-data = <5768 5335 5125 4999 4956 4945>,
			<5781 5340 5130 4999 4956 4945>,
			<5795 5347 5133 4999 4956 4946>,
			<5809 5352 5136 4999 4956 4947>,
			<5819 5356 5138 5000 4957 4947>,
			<5823 5358 5138 5001 4958 4948>,
			<5821 5357 5137 5002 4960 4949>,
			<5817 5355 5136 5003 4961 4950>,
			<5817 5354 5136 5004 4963 4951>,
			<5820 5353 5136 5005 4964 4952>,
			<5823 5353 5136 5007 4966 4954>,
			<5825 5353 5138 5009 4968 4956>,
			<5827 5355 5142 5012 4970 4958>,
			<5824 5361 5147 5015 4972 4960>,
			<5806 5375 5154 5018 4974 4962>,
			<5786 5381 5160 5023 4976 4964>,
			<5766 5363 5164 5027 4979 4966>,
			<5747 5335 5166 5032 4983 4968>,
			<5737 5322 5162 5040 4989 4973>,
			<5732 5313 5144 5049 4996 4978>,
			<5727 5306 5128 5051 4998 4980>,
			<5718 5298 5113 5031 4987 4972>,
			<5708 5290 5102 5009 4973 4961>,
			<5704 5286 5097 5000 4965 4955>,
			<5702 5282 5093 4994 4959 4949>,
			<5703 5279 5092 4992 4957 4947>,
			<5717 5275 5091 4993 4958 4948>,
			<5743 5272 5091 4995 4959 4950>,
			<5769 5272 5092 4996 4961 4952>,
			<5797 5272 5094 4999 4964 4954>,
			<5827 5274 5094 5001 4967 4956>,
			<5860 5286 5092 5004 4971 4959>,
			<5896 5305 5091 5007 4974 4962>,
			<5935 5325 5092 5010 4975 4964>,
			<5976 5349 5095 5013 4976 4966>,
			<6021 5377 5100 5013 4976 4966>,
			<6070 5411 5112 5010 4971 4959>,
			<6123 5448 5125 5007 4966 4953>,
			<6179 5483 5139 5003 4963 4952>,
			<6236 5518 5152 5001 4961 4952>,
			<6297 5556 5166 5001 4961 4952>,
			<6363 5598 5179 5003 4962 4953>,
			<6434 5644 5196 5005 4962 4953>,
			<6517 5698 5218 5007 4962 4953>,
			<6631 5771 5236 5003 4955 4945>,
			<6708 5834 5241 5004 4960 4950>,
			<6897 5915 5274 5010 4964 4953>,
			<7193 6031 5311 5018 4968 4959>,
			<7684 6189 5369 5030 4977 4972>,
			<8490 6445 5442 5040 4992 4984>,
			<10051 7056 5539 5038 4973 4960>,
			<13567 8521 5692 5030 4966 4956>,
			<24143 13355 6127 5051 4970 4960>,
			<65535 39089 7944 5086 4984 4972>,
			<65535 39089 7944 5086 4984 4972>,
			<65535 39089 7944 5086 4984 4972>;
	};

};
